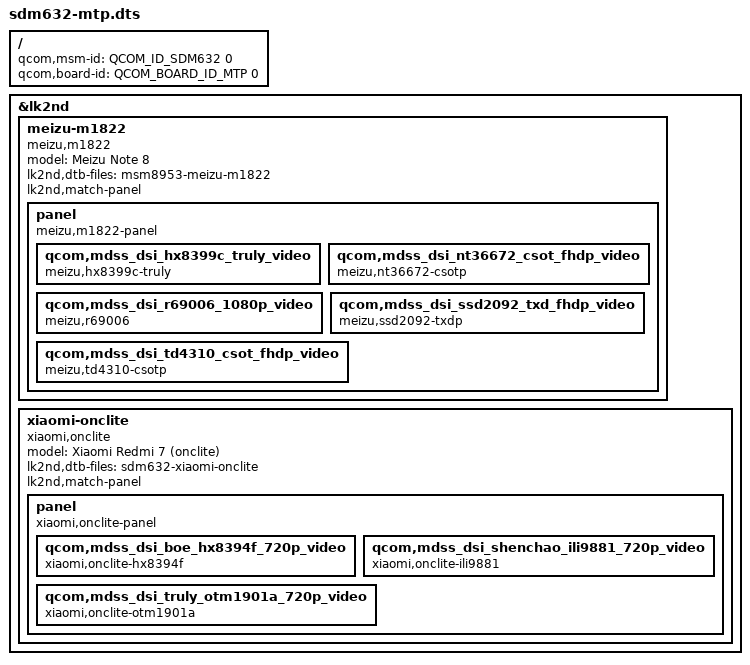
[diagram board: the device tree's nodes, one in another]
// SPDX-License-Identifier: GPL-2.0-only

/dts-v1/;

#include <skeleton64.dtsi>
#include <lk2nd.dtsi>

/ {
	qcom,msm-id = <QCOM_ID_SDM632 0>;
	qcom,board-id = <QCOM_BOARD_ID_MTP 0>;
	/* Bootloader appears to really want to access symbols */
	__symbols__ {};
};

&lk2nd {
	meizu-m1822 {
		model = "Meizu Note 8";
		compatible = "meizu,m1822";
		lk2nd,dtb-files = "msm8953-meizu-m1822";
		lk2nd,match-panel;

		panel {
			compatible = "meizu,m1822-panel", "lk2nd,panel";

			qcom,mdss_dsi_hx8399c_truly_video {
				compatible = "meizu,hx8399c-truly";
			};

			qcom,mdss_dsi_nt36672_csot_fhdp_video {
				compatible = "meizu,nt36672-csotp";
			};

			qcom,mdss_dsi_r69006_1080p_video {
				compatible = "meizu,r69006";
			};

			qcom,mdss_dsi_ssd2092_txd_fhdp_video {
				compatible = "meizu,ssd2092-txdp";
			};

			qcom,mdss_dsi_td4310_csot_fhdp_video {
				compatible = "meizu,td4310-csotp";
			};
		};
	};

	xiaomi-onclite {
		model = "Xiaomi Redmi 7 (onclite)";
		compatible = "xiaomi,onclite";
		lk2nd,dtb-files="sdm632-xiaomi-onclite";
		lk2nd,match-panel;

		panel {
			compatible = "xiaomi,onclite-panel", "lk2nd,panel";

			qcom,mdss_dsi_boe_hx8394f_720p_video {
				compatible = "xiaomi,onclite-hx8394f";
			};
			qcom,mdss_dsi_shenchao_ili9881_720p_video {
				compatible = "xiaomi,onclite-ili9881";
			};
			qcom,mdss_dsi_truly_otm1901a_720p_video {
				compatible = "xiaomi,onclite-otm1901a";
			};
		};
	};
};
